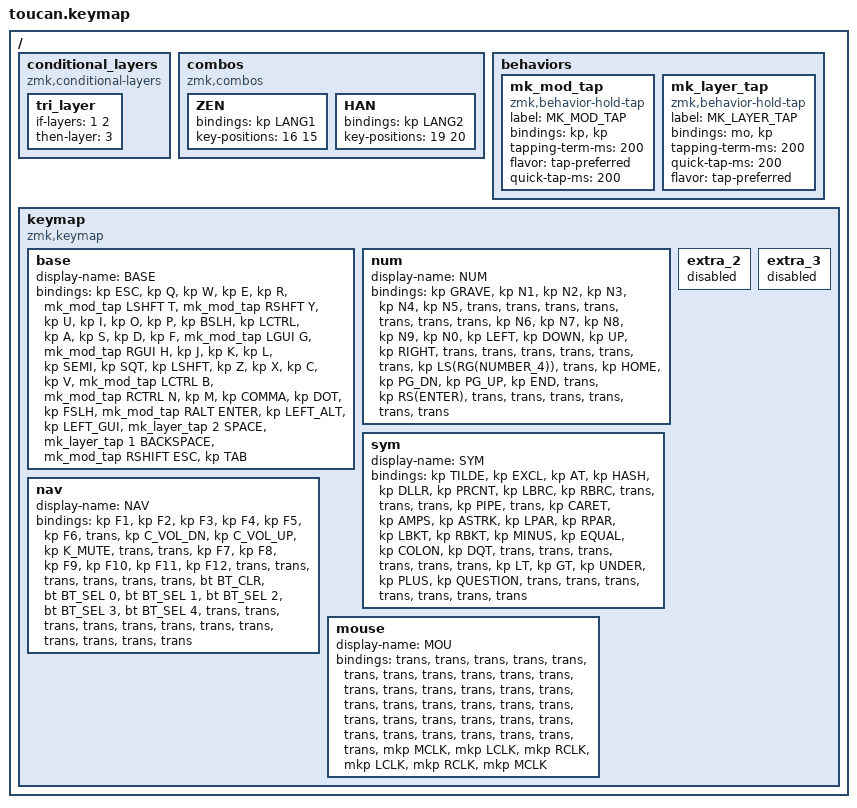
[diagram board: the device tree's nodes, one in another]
#include <behaviors.dtsi>
#include <dt-bindings/zmk/bt.h>
#include <dt-bindings/zmk/keys.h>
#include <dt-bindings/zmk/pointing.h>

#define BASE 0
#define NAV  1
#define SYM  2
#define ADJ  3

/ {
    conditional_layers {
        compatible = "zmk,conditional-layers";

        tri_layer {
            if-layers = <1 2>;
            then-layer = <3>;
        };
    };

    combos {
        compatible = "zmk,combos";

        ZEN {
            bindings = <&kp LANG1>;
            key-positions = <16 15>;
        };

        HAN {
            bindings = <&kp LANG2>;
            key-positions = <19 20>;
        };
    };

    behaviors {
        mk_mod_tap: mk_mod_tap {
            compatible = "zmk,behavior-hold-tap";
            label = "MK_MOD_TAP";
            bindings = <&kp>, <&kp>;

            #binding-cells = <2>;
            tapping-term-ms = <200>;
            flavor = "tap-preferred";
            quick-tap-ms = <200>;
        };

        mk_layer_tap: mk_layer_tap {
            compatible = "zmk,behavior-hold-tap";
            label = "MK_LAYER_TAP";
            bindings = <&mo>, <&kp>;

            #binding-cells = <2>;
            tapping-term-ms = <200>;
            quick-tap-ms = <200>;
            flavor = "tap-preferred";
        };
    };

    keymap {
        compatible = "zmk,keymap";

        base {
            display-name = "BASE";
            bindings = <
&kp ESC  &kp Q  &kp W  &kp E  &kp R  &mk_mod_tap LSHFT T  &mk_mod_tap RSHFT Y  &kp U  &kp I  &kp O  &kp P  &kp BSLH  &kp LCTRL  &kp A  &kp S  &kp D  &kp F  &mk_mod_tap LGUI G  &mk_mod_tap RGUI H  &kp J  &kp K  &kp L  &kp SEMI  &kp SQT  &kp LSHFT  &kp Z  &kp X  &kp C  &kp V  &mk_mod_tap LCTRL B  &mk_mod_tap RCTRL N  &kp M  &kp COMMA  &kp DOT  &kp FSLH  &mk_mod_tap RALT ENTER  &kp LEFT_ALT  &kp LEFT_GUI  &mk_layer_tap 2 SPACE  &mk_layer_tap 1 BACKSPACE  &mk_mod_tap RSHIFT ESC  &kp TAB
            >;
        };

        num {
            display-name = "NUM";
            bindings = <
&kp GRAVE  &kp N1  &kp N2  &kp N3  &kp N4  &kp N5  &trans  &trans  &trans  &trans  &trans  &trans  &trans  &kp N6  &kp N7  &kp N8  &kp N9  &kp N0  &kp LEFT  &kp DOWN  &kp UP  &kp RIGHT  &trans  &trans  &trans  &trans  &trans  &trans  &kp LS(RG(NUMBER_4))  &trans  &kp HOME  &kp PG_DN  &kp PG_UP  &kp END  &trans  &kp RS(ENTER)  &trans  &trans  &trans  &trans  &trans  &trans
            >;
        };

        sym {
            display-name = "SYM";
            bindings = <
&kp TILDE  &kp EXCL  &kp AT  &kp HASH  &kp DLLR  &kp PRCNT  &kp LBRC  &kp RBRC  &trans  &trans  &trans  &kp PIPE  &trans  &kp CARET  &kp AMPS  &kp ASTRK  &kp LPAR  &kp RPAR  &kp LBKT  &kp RBKT  &kp MINUS  &kp EQUAL  &kp COLON  &kp DQT  &trans  &trans  &trans  &trans  &trans  &trans  &kp LT  &kp GT  &kp UNDER  &kp PLUS  &kp QUESTION  &trans  &trans  &trans  &trans  &trans  &trans  &trans
            >;
        };

        nav {
            display-name = "NAV";
            bindings = <
&kp F1  &kp F2  &kp F3  &kp F4  &kp F5  &kp F6  &trans  &kp C_VOL_DN  &kp C_VOL_UP  &kp K_MUTE  &trans  &trans  &kp F7  &kp F8  &kp F9  &kp F10  &kp F11  &kp F12  &trans  &trans  &trans  &trans  &trans  &trans  &bt BT_CLR  &bt BT_SEL 0  &bt BT_SEL 1  &bt BT_SEL 2  &bt BT_SEL 3  &bt BT_SEL 4  &trans  &trans  &trans  &trans  &trans  &trans  &trans  &trans  &trans  &trans  &trans  &trans
            >;
        };

        mouse {
            display-name = "MOU";
            bindings = <
&trans  &trans  &trans  &trans  &trans  &trans  &trans  &trans  &trans  &trans  &trans  &trans  &trans  &trans  &trans  &trans  &trans  &trans  &trans  &trans  &trans  &trans  &trans  &trans  &trans  &trans  &trans  &trans  &trans  &trans  &trans  &trans  &trans  &trans  &trans  &trans  &mkp MCLK  &mkp LCLK  &mkp RCLK  &mkp LCLK  &mkp RCLK  &mkp MCLK
            >;
        };

        extra_2 { status = "reserved"; };

        extra_3 { status = "reserved"; };
    };
};
